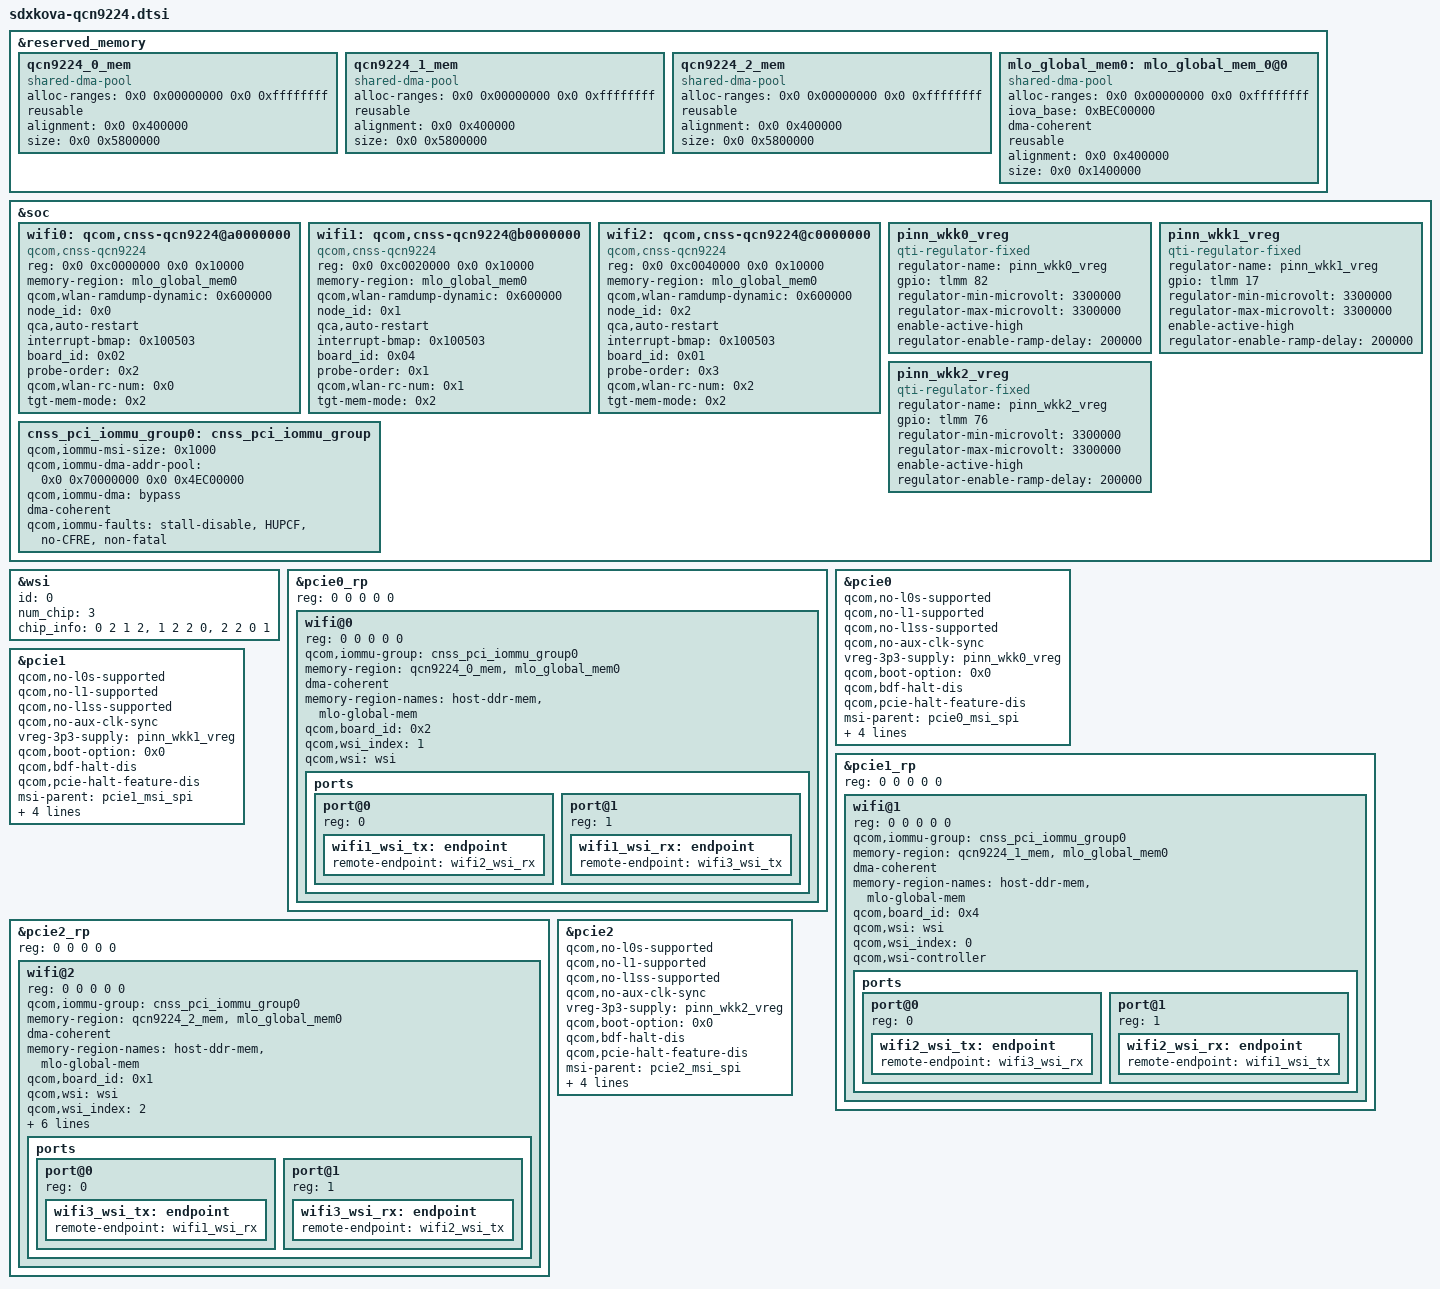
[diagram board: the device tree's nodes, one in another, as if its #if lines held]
// SPDX-License-Identifier: BSD-3-Clause
/*
 * Copyright (c) Qualcomm Technologies, Inc. and/or its subsidiaries.
 */

&reserved_memory {
	#address-cells = <2>;
	#size-cells = <2>;
	ranges;

	qcn9224_0_mem: qcn9224_0_mem {
		compatible = "shared-dma-pool";
		alloc-ranges = <0x0 0x00000000 0x0 0xffffffff>;
		reusable;
		alignment = <0x0 0x400000>;
#ifndef __WLAN_LITE_PROFILE__
		size = <0x0 0x5800000>;
#else
		size = <0x0 0x2000000>;
#endif
	};

	qcn9224_1_mem: qcn9224_1_mem {
		compatible = "shared-dma-pool";
		alloc-ranges = <0x0 0x00000000 0x0 0xffffffff>;
		reusable;
		alignment = <0x0 0x400000>;
#ifndef __WLAN_LITE_PROFILE__
		size = <0x0 0x5800000>;
#else
		size = <0x0 0x2000000>;
#endif

	};

	qcn9224_2_mem: qcn9224_2_mem {
		compatible = "shared-dma-pool";
		alloc-ranges = <0x0 0x00000000 0x0 0xffffffff>;
		reusable;
		alignment = <0x0 0x400000>;
#ifndef __WLAN_LITE_PROFILE__
		size = <0x0 0x5800000>;
#else
		size = <0x0 0x2000000>;
#endif

	};

	mlo_global_mem0: mlo_global_mem_0@0 {
		compatible = "shared-dma-pool";
		alloc-ranges = <0x0 0x00000000 0x0 0xffffffff>;
		iova_base = <0xBEC00000>;
		dma-coherent;
		reusable;
		alignment = <0x0 0x400000>;
#ifndef __WLAN_LITE_PROFILE__
		size = <0x0 0x1400000>;
#else
		size = <0x0 0x1000000>;
#endif

	};
};

&soc {
	wifi0: qcom,cnss-qcn9224@a0000000 {
			compatible  = "qcom,cnss-qcn9224";
			reg = <0x0 0xc0000000 0x0 0x10000>;
			reg-names = "smmu_iova_ipa";
			memory-region = <&mlo_global_mem0>;
			qcom,wlan-ramdump-dynamic = <0x600000>;
			node_id = <0x0>;
			qca,auto-restart;
			interrupt-bmap = <0x100503>;
			board_id = <0x02>;
			probe-order = <0x2>;
			qcom,wlan-rc-num = <0x0>;
#ifdef __WLAN_LITE_PROFILE__
			tgt-mem-mode = <0x2>;
#endif
			status = "ok";
	};

	wifi1: qcom,cnss-qcn9224@b0000000 {
			compatible  = "qcom,cnss-qcn9224";
			reg = <0x0 0xc0020000 0x0 0x10000>;
			reg-names = "smmu_iova_ipa";
			memory-region = <&mlo_global_mem0>;
			qcom,wlan-ramdump-dynamic = <0x600000>;
			node_id = <0x1>;
			qca,auto-restart;
			interrupt-bmap = <0x100503>;
			board_id = <0x04>;
			probe-order = <0x1>;
			qcom,wlan-rc-num = <0x1>;
#ifdef __WLAN_LITE_PROFILE__
			tgt-mem-mode = <0x2>;
#endif
			status = "ok";
	};

	wifi2: qcom,cnss-qcn9224@c0000000 {
			compatible  = "qcom,cnss-qcn9224";
			reg = <0x0 0xc0040000 0x0 0x10000>;
			reg-names = "smmu_iova_ipa";
			memory-region = <&mlo_global_mem0>;
			qcom,wlan-ramdump-dynamic = <0x600000>;
			node_id = <0x2>;
			qca,auto-restart;
			interrupt-bmap = <0x100503>;
			board_id = <0x01>;
			probe-order = <0x3>;
			qcom,wlan-rc-num = <0x2>;
#ifdef __WLAN_LITE_PROFILE__
			tgt-mem-mode = <0x2>;
#endif
			status = "ok";
	};

	pinn_wkk0_vreg: pinn_wkk0_vreg {
			compatible = "qti-regulator-fixed";
			regulator-name = "pinn_wkk0_vreg";
			gpio = <&tlmm 82 GPIO_ACTIVE_HIGH>;
			regulator-min-microvolt = <3300000>;
			regulator-max-microvolt = <3300000>;
			enable-active-high;
			regulator-enable-ramp-delay = <200000>;
	};

	pinn_wkk1_vreg: pinn_wkk1_vreg {
			compatible = "qti-regulator-fixed";
			regulator-name = "pinn_wkk1_vreg";
			gpio = <&tlmm 17 GPIO_ACTIVE_HIGH>;
			regulator-min-microvolt = <3300000>;
			regulator-max-microvolt = <3300000>;
			enable-active-high;
			regulator-enable-ramp-delay = <200000>;
	};

	pinn_wkk2_vreg: pinn_wkk2_vreg {
			compatible = "qti-regulator-fixed";
			regulator-name = "pinn_wkk2_vreg";
			gpio = <&tlmm 76 GPIO_ACTIVE_HIGH>;
			regulator-min-microvolt = <3300000>;
			regulator-max-microvolt = <3300000>;
			enable-active-high;
			regulator-enable-ramp-delay = <200000>;
	};

	cnss_pci_iommu_group0: cnss_pci_iommu_group {
			qcom,iommu-msi-size = <0x1000>;
			qcom,iommu-dma-addr-pool = <0x0 0x70000000 0x0 0x4EC00000>;
#ifdef __WLAN_UD__
			qcom,iommu-dma = "bypass";
#else
			qcom,iommu-dma = "fastmap";
#endif
			dma-coherent;
			qcom,iommu-faults = "stall-disable", "HUPCF", "no-CFRE",
					    "non-fatal";
	};

};

#ifdef __WLAN_UD__
&wsi {
	id = <0>;
	num_chip = <3>;
	status = "okay";
	chip_info = <0 2 1 2>,
		    <1 2 2 0>,
		    <2 2 0 1>;
	status = "okay";
};

#endif

&pcie0_rp {
	reg = <0 0 0 0 0>;
	#address-cells = <5>;
	#size-cells = <0>;
#ifdef __WLAN_UD__
	wifi@0 {
		reg = <0 0 0 0 0>;
		qcom,iommu-group = <&cnss_pci_iommu_group0>;
		memory-region = <&qcn9224_0_mem>, <&mlo_global_mem0>;
		#address-cells = <1>;
		#size-cells = <1>;
		dma-coherent;
		memory-region-names = "host-ddr-mem", "mlo-global-mem";
		qcom,board_id = <0x2>;
		qcom,wsi_index = <1>;
		qcom,wsi = <&wsi>;
		ports {
			#address-cells = <1>;
			#size-cells = <0>;

			port@0 {
				reg = <0>;

				wifi1_wsi_tx: endpoint {
					remote-endpoint = <&wifi2_wsi_rx>;
				};
			};

			port@1 {
				reg = <1>;

				wifi1_wsi_rx: endpoint {
					remote-endpoint = <&wifi3_wsi_tx>;
				};
			};
		};
	};

#else
	cnss_pci0: cnss_pci0 {
		reg = <0 0 0 0 0>;
		qcom,iommu-group = <&cnss_pci_iommu_group0>;
		memory-region = <&qcn9224_0_mem>;
		#address-cells = <1>;
		#size-cells = <1>;
		dma-coherent;
	};

#endif
};

&pcie0 {
	qcom,no-l0s-supported;
	qcom,no-l1-supported;
	qcom,no-l1ss-supported;
	qcom,no-aux-clk-sync;
	vreg-3p3-supply = <&pinn_wkk0_vreg>;
	qcom,boot-option = <0x0>;
	qcom,bdf-halt-dis;
	qcom,pcie-halt-feature-dis;
	msi-parent = <&pcie0_msi_spi>;
	qcom,pcie-phy-ver = <115>;
	qcom,phy-sequence = <0x1240 0x03 0x0
				0x0030 0x18 0x0
				0x0034 0x03 0x0
				0x0078 0x01 0x0
				0x007c 0x10 0x0
				0x0080 0x51 0x0
				0x00ac 0x34 0x0
				0x0208 0x0c 0x0
				0x020c 0x0a 0x0
				0x0218 0x04 0x0
				0x0220 0x16 0x0
				0x0234 0x00 0x0
				0x029c 0x80 0x0
				0x02a0 0x7c 0x0
				0x02b0 0x00 0x0
				0x02b4 0x05 0x0
				0x02d4 0x10 0x0
				0x02e8 0x0a 0x0
				0x030c 0x11 0x0
				0x0320 0x0b 0x0
				0x0348 0x1c 0x0
				0x0388 0x20 0x0
				0x0394 0x30 0x0
				0x03dc 0x09 0x0
				0x03f4 0xd4 0x0
				0x03f8 0x73 0x0
				0x03fc 0x18 0x0
				0x0400 0x9a 0x0
				0x0404 0x36 0x0
				0x0408 0xb6 0x0
				0x040c 0xee 0x0
				0x0410 0xcb 0x0
				0x0414 0xcb 0x0
				0x0418 0xe0 0x0
				0x041c 0xdf 0x0
				0x0420 0x78 0x0
				0x0424 0x76 0x0
				0x0428 0xff 0x0
				0x02e0 0x00 0x0
				0x0830 0x18 0x0
				0x0834 0x03 0x0
				0x0878 0x01 0x0
				0x087c 0x00 0x0
				0x0880 0x51 0x0
				0x08ac 0x34 0x0
				0x0a08 0x0c 0x0
				0x0a0c 0x0a 0x0
				0x0a18 0x04 0x0
				0x0a20 0x16 0x0
				0x0a34 0x00 0x0
				0x0a9c 0x80 0x0
				0x0aa0 0x7c 0x0
				0x0ab0 0x00 0x0
				0x0ab4 0x05 0x0
				0x0ad4 0x10 0x0
				0x0ae8 0x0a 0x0
				0x0b0c 0x0D 0x0
				0x0b20 0x0b 0x0
				0x0b48 0x1c 0x0
				0x0b88 0x20 0x0
				0x0b94 0x30 0x0
				0x0bdc 0x09 0x0
				0x0bf4 0xd4 0x0
				0x0bf8 0x73 0x0
				0x0bfc 0x18 0x0
				0x0c00 0x9a 0x0
				0x0c04 0x36 0x0
				0x0c08 0xb6 0x0
				0x0c0c 0xee 0x0
				0x0c10 0xcb 0x0
				0x0c14 0xcb 0x0
				0x0c18 0xe0 0x0
				0x0c1c 0xdf 0x0
				0x0c20 0x78 0x0
				0x0c24 0x76 0x0
				0x0c28 0xff 0x0
				0x0ae0 0x00 0x0
				0x0ea0 0x01 0x0
				0x0eb4 0x00 0x0
				0x0eb8 0x00 0x0
				0x0ec4 0x02 0x0
				0x0ec8 0x0d 0x0
				0x0ed4 0xd4 0x0
				0x0ed8 0x12 0x0
				0x0edc 0xdb 0x0
				0x0ee0 0x9a 0x0
				0x0ee4 0x35 0x0
				0x0ee8 0xb6 0x0
				0x0eec 0x64 0x0
				0x0ef0 0x1f 0x0
				0x0ef4 0x1f 0x0
				0x0ef8 0x1f 0x0
				0x0efc 0x1f 0x0
				0x0f00 0x1f 0x0
				0x0f04 0x1f 0x0
				0x0f0c 0x1f 0x0
				0x0f14 0x1f 0x0
				0x0f1c 0x1f 0x0
				0x0f28 0x5b 0x0
				0x1000 0x97 0x0
				0x1004 0x0c 0x0
				0x1010 0x06 0x0
				0x1014 0x16 0x0
				0x1018 0x36 0x0
				0x101c 0x04 0x0
				0x1020 0x14 0x0
				0x1024 0x34 0x0
				0x1028 0xd0 0x0
				0x1030 0x55 0x0
				0x1034 0x55 0x0
				0x1038 0x05 0x0
				0x103c 0x12 0x0
				0x1060 0xde 0x0
				0x1064 0x07 0x0
				0x1070 0x06 0x0
				0x1074 0x16 0x0
				0x1078 0x36 0x0
				0x107c 0x0a 0x0
				0x1080 0x0a 0x0
				0x1084 0x1a 0x0
				0x1088 0x82 0x0
				0x1090 0x55 0x0
				0x1094 0x55 0x0
				0x1098 0x03 0x0
				0x109c 0x00 0x0
				0x10bc 0x0e 0x0
				0x10c0 0x01 0x0
				0x10cc 0x31 0x0
				0x10d0 0x01 0x0
				0x10d8 0x40 0x0
				0x10dc 0x14 0x0
				0x10e0 0x90 0x0
				0x10e4 0x82 0x0
				0x10f4 0x0f 0x0
				0x1110 0x08 0x0
				0x1120 0x46 0x0
				0x1124 0x04 0x0
				0x1140 0x14 0x0
				0x1164 0x34 0x0
				0x1170 0xa0 0x0
				0x1174 0x06 0x0
				0x1184 0x88 0x0
				0x1188 0x14 0x0
				0x1198 0x0f 0x0
				0x1378 0x2e 0x0
				0x1390 0xcc 0x0
				0x13f8 0x00 0x0
				0x13fc 0x22 0x0
				0x141c 0xc1 0x0
				0x129c 0x83 0x0
				0x12a0 0x09 0x0
				0x12a4 0xa2 0x0
				0x1450 0x03 0x0
				0x1490 0x00 0x0
				0x14a0 0x16 0x0
				0x14f0 0x27 0x0
				0x14f4 0x27 0x0
				0x1508 0x02 0x0
				0x155c 0x2e 0x0
				0x157c 0x03 0x0
				0x1584 0x28 0x0
				0x13dc 0x04 0x0
				0x13e0 0x02 0x0
				0x1418 0xc0 0x0
				0x140c 0x1d 0x0
				0x158c 0x0f 0x0
				0x15ac 0xf2 0x0
				0x15c0 0xf2 0x0
				0x1370 0x17 0x0
				0x1a38 0x00 0x0
				0x1e38 0x00 0x0
				0x1e24 0x00 0x0
				0x1e28 0x00 0x0
				0x1200 0x00 0x0
				0x1244 0x03 0x0>;
	dma-coherent;
	status = "ok";
};

&pcie1_rp {
	reg = <0 0 0 0 0>;
	#address-cells = <5>;
	#size-cells = <0>;
#ifdef __WLAN_UD__
	wifi@1 {
		reg = <0 0 0 0 0>;
		qcom,iommu-group = <&cnss_pci_iommu_group0>;
		memory-region = <&qcn9224_1_mem>, <&mlo_global_mem0>;
		#address-cells = <1>;
		#size-cells = <1>;
		dma-coherent;
		memory-region-names = "host-ddr-mem", "mlo-global-mem";
		qcom,board_id = <0x4>;
		qcom,wsi = <&wsi>;
		qcom,wsi_index = <0>;
		qcom,wsi-controller;
		ports {
			#address-cells = <1>;
			#size-cells = <0>;

			port@0 {
				reg = <0>;

				wifi2_wsi_tx: endpoint {
					remote-endpoint = <&wifi3_wsi_rx>;
				};
			};

			port@1 {
				reg = <1>;

				wifi2_wsi_rx: endpoint {
					remote-endpoint = <&wifi1_wsi_tx>;
				};
			};
		};
	};

#else
	cnss_pci1: cnss_pci1 {
		reg = <0 0 0 0 0>;
		qcom,iommu-group = <&cnss_pci_iommu_group0>;
		memory-region = <&qcn9224_1_mem>;
		#address-cells = <1>;
		#size-cells = <1>;
		dma-coherent;
	};

#endif
};

&pcie1 {
	qcom,no-l0s-supported;
	qcom,no-l1-supported;
	qcom,no-l1ss-supported;
	qcom,no-aux-clk-sync;
	vreg-3p3-supply = <&pinn_wkk1_vreg>;
	qcom,boot-option = <0x0>;
	qcom,bdf-halt-dis;
	qcom,pcie-halt-feature-dis;
	msi-parent = <&pcie1_msi_spi>;
	qcom,pcie-phy-ver = <113>;
	qcom,phy-sequence = <0x0240 0x03 0x0
				0x00c0 0x01 0x0
				0x00cc 0x31 0x0
				0x00d0 0x01 0x0
				0x0060 0xff 0x0
				0x0064 0x06 0x0
				0x0000 0x4c 0x0
				0x0004 0x06 0x0
				0x00e0 0x90 0x0
				0x00e4 0x82 0x0
				0x00f4 0x07 0x0
				0x0070 0x02 0x0
				0x0010 0x02 0x0
				0x0074 0x16 0x0
				0x0014 0x16 0x0
				0x0078 0x36 0x0
				0x0018 0x36 0x0
				0x0110 0x08 0x0
				0x00bc 0x0e 0x0
				0x0120 0x42 0x0
				0x0080 0x08 0x0
				0x0084 0x1a 0x0
				0x0020 0x14 0x0
				0x0024 0x34 0x0
				0x0088 0x82 0x0
				0x0028 0x68 0x0
				0x0090 0xab 0x0
				0x0094 0xea 0x0
				0x0098 0x02 0x0
				0x0030 0xab 0x0
				0x0034 0xaa 0x0
				0x0038 0x02 0x0
				0x0140 0x14 0x0
				0x0164 0x34 0x0
				0x003c 0x01 0x0
				0x001c 0x04 0x0
				0x0174 0x16 0x0
				0x01bc 0x0f 0x0
				0x0170 0xa0 0x0
				0x11a4 0x38 0x0
				0x10dc 0x0d 0x0
				0x1160 0xbf 0x0
				0x1164 0xbf 0x0
				0x1168 0xb7 0x0
				0x116c 0xef 0x0
				0x115c 0x3f 0x0
				0x1174 0x5c 0x0
				0x1178 0x9c 0x0
				0x117c 0x1a 0x0
				0x1180 0x89 0x0
				0x1170 0xdc 0x0
				0x1188 0x94 0x0
				0x118c 0x5b 0x0
				0x1190 0x1a 0x0
				0x1194 0x89 0x0
				0x10cc 0x00 0x0
				0x1008 0x09 0x0
				0x1014 0x05 0x0
				0x104c 0x08 0x0
				0x1050 0x08 0x0
				0x10d8 0x0f 0x0
				0x1118 0x1c 0x0
				0x10f8 0x07 0x0
				0x11f8 0x08 0x0
				0x1600 0x00 0x0
				0x0e84 0x15 0x0
				0x0e90 0x3f 0x0
				0x0ee4 0x02 0x0
				0x0e40 0x06 0x0
				0x0e3c 0x18 0x0
				0x19a4 0x38 0x0
				0x18dc 0x0d 0x0
				0x1960 0xbf 0x0
				0x1964 0xbf 0x0
				0x1968 0xb7 0x0
				0x196c 0xef 0x0
				0x195c 0x3f 0x0
				0x1974 0x5c 0x0
				0x1978 0x9c 0x0
				0x197c 0x1a 0x0
				0x1980 0x89 0x0
				0x1970 0xdc 0x0
				0x1988 0x94 0x0
				0x198c 0x5b 0x0
				0x1990 0x1a 0x0
				0x1994 0x89 0x0
				0x18cc 0x00 0x0
				0x1808 0x09 0x0
				0x1814 0x05 0x0
				0x184c 0x08 0x0
				0x1850 0x08 0x0
				0x18d8 0x0f 0x0
				0x1918 0x1c 0x0
				0x18f8 0x07 0x0
				0x19f8 0x08 0x0
				0x1684 0x15 0x0
				0x1690 0x3f 0x0
				0x16e4 0x02 0x0
				0x1640 0x06 0x0
				0x163c 0x18 0x0
				0x02dc 0x05 0x0
				0x0388 0x77 0x0
				0x0398 0x0b 0x0
				0x06a4 0x1e 0x0
				0x06f4 0x27 0x0
				0x03e0 0x0f 0x0
				0x060c 0x1d 0x0
				0x0614 0x07 0x0
				0x0620 0xc1 0x0
				0x0694 0x00 0x0
				0x03d0 0x8c 0x0
				0x0368 0x17 0x0
				0x0370 0x2e 0x0
				0x1424 0x00 0x0
				0x1428 0x00 0x0
				0x0200 0x00 0x0
				0x0244 0x03 0x0>;
	dma-coherent;
	status = "ok";
};

&pcie2_rp {
	reg = <0 0 0 0 0>;
	#address-cells = <5>;
	#size-cells = <0>;
#ifdef __WLAN_UD__
	wifi@2 {
		reg = <0 0 0 0 0>;
		qcom,iommu-group = <&cnss_pci_iommu_group0>;
		memory-region = <&qcn9224_2_mem>, <&mlo_global_mem0>;
		#address-cells = <1>;
		#size-cells = <1>;
		dma-coherent;
		memory-region-names = "host-ddr-mem", "mlo-global-mem";
		qcom,board_id = <0x1>;
		qcom,wsi = <&wsi>;
		qcom,wsi_index = <2>;
		qcom,pta-num = <0>;
		qcom,coex-mode = <0x2>;
		qcom,bt-active-time = <0x18>;
		qcom,bt-priority-time = <0x12>;
		qcom,coex-algo = <0x2>;
		qcom,pta-priority = <0x80800505>;
		ports {
			#address-cells = <1>;
			#size-cells = <0>;

			port@0 {
				reg = <0>;

				wifi3_wsi_tx: endpoint {
					remote-endpoint = <&wifi1_wsi_rx>;
				};
			};

			port@1 {
				reg = <1>;

				wifi3_wsi_rx: endpoint {
					remote-endpoint = <&wifi2_wsi_tx>;
				};
			};
		};
	};

#else
	cnss_pci2: cnss_pci2 {
		reg = <0 0 0 0 0>;
		qcom,iommu-group = <&cnss_pci_iommu_group0>;
		memory-region = <&qcn9224_2_mem>;
		#address-cells = <1>;
		#size-cells = <1>;
		dma-coherent;
	};

#endif
};

&pcie2 {
	qcom,no-l0s-supported;
	qcom,no-l1-supported;
	qcom,no-l1ss-supported;
	qcom,no-aux-clk-sync;
	vreg-3p3-supply = <&pinn_wkk2_vreg>;
	qcom,boot-option = <0x0>;
	qcom,bdf-halt-dis;
	qcom,pcie-halt-feature-dis;
	msi-parent = <&pcie2_msi_spi>;
	qcom,pcie-phy-ver = <115>;
	qcom,phy-sequence = <0x0240 0x03 0x0
				0x0000 0x4c 0x0
				0x0004 0x06 0x0
				0x0010 0x02 0x0
				0x0014 0x16 0x0
				0x0018 0x36 0x0
				0x001c 0x04 0x0
				0x0020 0x14 0x0
				0x0024 0x34 0x0
				0x0028 0x68 0x0
				0x0030 0xab 0x0
				0x0034 0xaa 0x0
				0x0038 0x02 0x0
				0x003c 0x01 0x0
				0x0048 0xb4 0x0
				0x004c 0x03 0x0
				0x0060 0xde 0x0
				0x0064 0x07 0x0
				0x0070 0x02 0x0
				0x0074 0x16 0x0
				0x0078 0x36 0x0
				0x0080 0x0a 0x0
				0x0084 0x1a 0x0
				0x0088 0x82 0x0
				0x0090 0xab 0x0
				0x0094 0xea 0x0
				0x0098 0x02 0x0
				0x00a8 0x24 0x0
				0x00bc 0x0e 0x0
				0x00c0 0x01 0x0
				0x00cc 0x31 0x0
				0x00d0 0x01 0x0
				0x00e0 0x90 0x0
				0x00e4 0x82 0x0
				0x00f4 0x07 0x0
				0x0110 0x08 0x0
				0x0120 0x42 0x0
				0x0140 0x14 0x0
				0x0164 0x34 0x0
				0x0170 0xa0 0x0
				0x0174 0x16 0x0
				0x01bc 0x0f 0x0
				0x02dc 0x05 0x0
				0x0370 0x2e 0x0
				0x0388 0x77 0x0
				0x0398 0x0b 0x0
				0x03d0 0x0c 0x0
				0x03e0 0x0f 0x0
				0x060c 0x1d 0x0
				0x0620 0xc1 0x0
				0x0654 0x00 0x0
				0x0694 0x00 0x0
				0x06f4 0x27 0x0
				0x0e3c 0x17 0x0
				0x0e40 0x06 0x0
				0x0e84 0x15 0x0
				0x0e90 0x3f 0x0
				0x0ea4 0x12 0x0
				0x0ee4 0x02 0x0
				0x1008 0x09 0x0
				0x1014 0x05 0x0
				0x1034 0x7f 0x0
				0x1044 0xf0 0x0
				0x104c 0x08 0x0
				0x1050 0x08 0x0
				0x1060 0x30 0x0
				0x10cc 0xf0 0x0
				0x10d4 0x04 0x0
				0x10d8 0x0f 0x0
				0x10dc 0x0d 0x0
				0x10ec 0x0e 0x0
				0x10f0 0x4a 0x0
				0x10f4 0x0a 0x0
				0x10f8 0x07 0x0
				0x1110 0x14 0x0
				0x1118 0x0c 0x0
				0x115c 0x3f 0x0
				0x1160 0xbf 0x0
				0x1164 0xbf 0x0
				0x1168 0xb7 0x0
				0x116c 0xea 0x0
				0x1170 0xdc 0x0
				0x1174 0x5c 0x0
				0x1178 0x9c 0x0
				0x117c 0x1a 0x0
				0x1180 0x89 0x0
				0x1188 0x94 0x0
				0x118c 0x5b 0x0
				0x1190 0x1a 0x0
				0x1194 0x89 0x0
				0x11a4 0x38 0x0
				0x11f8 0x08 0x0
				0x0200 0x00 0x0
				0x0244 0x03 0x0>;
	dma-coherent;
	status = "ok";
};
